# AE101F4071542LH_CM55_HE_View register map
Vendor: Alif Semiconductor; Series: E1; File version: 1.0
CPU: CM55 r1p0, selectable endian, MPU, FPU, double-precision FPU, DSP, VTOR, 8 interrupt priority bits, 1 SAU regions
Registers are 32-bit, read-write, reset 0x0 unless marked. A register's access mark holds for its fields unless they carry their own. Offsets are from the block's base; [hi:lo] are bit positions; {n}, {i} and the like mark numbered series.

## LPGPIO_CTRL
Base 0x42007000
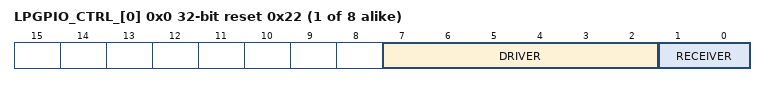
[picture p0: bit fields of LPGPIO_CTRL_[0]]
{0x0+4i} LPGPIO_CTRL_[{i}] (i=0..7) reset 0x22 — LPGPIO I/O Buffer Control Register
  [7:2] DRIVER — Driver configuration - Bit[7] selects driver mode: 0x0: Push-pull 0x1: Open drain - Bits[6-5] select driver strength: 0x0: 2 mA 0x1: 4 mA (default) 0x2: 8 mA 0x3: 12 mA - Bits[4-3] select driver disabled state: 0x0: Hi-Z 0x1: Pull-up 0x2: Pull-down 0x3: Bus keeper - Bit[2] selects slew rate: Note: Applicable only to 1.8-V I/Os (non-Flex) 0x0: Slow 0x1: Fast
  [1:0] RECEIVER — Receiver configuration - Bit[1] Schmitt trigger (hysteresis) enable: 0x0: Disabled 0x1: Enabled - Bit[0] receiver enable: 0x0: Disabled 0x1: Enabled

## LPCPI
Base 0x43003000
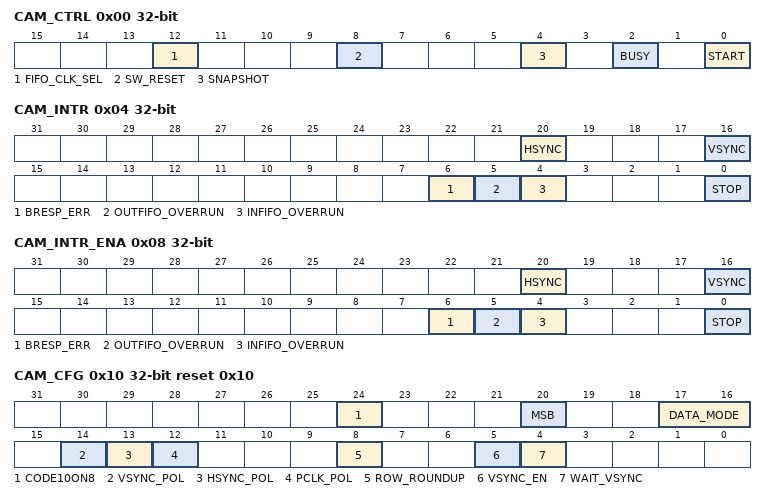
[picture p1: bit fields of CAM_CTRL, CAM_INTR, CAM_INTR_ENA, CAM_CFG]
0x00 CAM_CTRL — Camera Control Register
  [12] FIFO_CLK_SEL — Select clock source for the camera data input FIFO.
    0=Select internal clock for soft reset; 1=Select external camera clock for normal function mode
  [8] SW_RESET — Software reset. Software shall set then clear this bit.
    0=Not reset; 1=Reset
  [4] SNAPSHOT — Snapshot mode selection. Note: Setting this bit to value other than 1 will cause undefined behavior.
    1=Capture one frame then stop (snapshot mode)
  [2] BUSY ro — Status of video capture.
    0=Not capturing video; 1=Capturing video
  [0] START — Start video capture.
    0=No action; 1=Start video capture
0x04 CAM_INTR — Camera Interrupt Status Register
  [20] HSYNC wo write-1-clears — Rising edge of HSYNC signal.
  [16] VSYNC wo write-1-clears — Rising edge of VSYNC signal.
  [6] BRESP_ERR wo write-1-clears — AXI bus BRESP error.
  [5] OUTFIFO_OVERRUN wo write-1-clears — Output FIFO overrun.
  [4] INFIFO_OVERRUN wo write-1-clears — Input FIFO overrun.
  [0] STOP wo write-1-clears — Video capture stopped.
0x08 CAM_INTR_ENA — Camera Interrupt Enable Register
  [20] HSYNC — Rising edge of HSYNC signal.
  [16] VSYNC — Rising edge of VSYNC signal.
  [6] BRESP_ERR — AXI bus BRESP error.
  [5] OUTFIFO_OVERRUN — Output FIFO overrun.
  [4] INFIFO_OVERRUN — Input FIFO overrun.
  [0] STOP — Video capture stopped.
0x10 CAM_CFG reset 0x10 — Camera Configuration Register
  [24] CODE10ON8 — Special coding: transfer 10-bit coding over 8-bit data bus. Valid only when [DATA_MODE] field is set to 8-bit.
    0=Disable special 10-bit coding; 1=Enable special 10-bit coding
  [20] MSB — Select MSB/LSB Valid only when [DATA_MODE] field is set to 1-/2-/4-/8-bit.
    0=LSB; 1=MSB
  [17:16] DATA_MODE — Select video data mode.
    0=1-bit; 1=2-bit; 2=4-bit; 3=8-bit
  [14] VSYNC_POL — Set camera VSYNC polarity.
    0=Not invert VSYNC input; 1=Invert VSYNC input
  [13] HSYNC_POL — Set camera HSYNC polarity.
    0=Not invert HSYNC input; 1=Invert HSYNC input
  [12] PCLK_POL — Set camera PIXEL_CLK polarity.
    0=Not invert external camera PIXEL_CLK; 1=Invert external camera PIXEL_CLK
  [8] ROW_ROUNDUP — Round up pixel data to 64-bit at the end of each row.
    0=Not round up; 1=Round up pixel data to 64-bit at the end of each row
  [5] VSYNC_EN — Capture data when VSYNC is high.
    0=Capture data regardless of VSYNC status; 1=Capture data when VSYNC is high
  [4] WAIT_VSYNC — Capture video frame on the rising edge of VSYNC.
    0=Start video capture without waiting for VSYNC; 1=Start video capture on rising edge of VSYNC
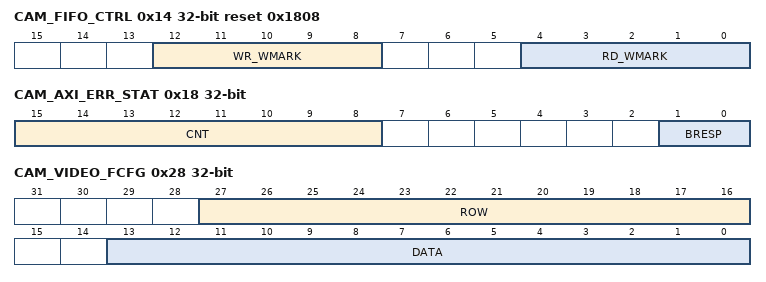
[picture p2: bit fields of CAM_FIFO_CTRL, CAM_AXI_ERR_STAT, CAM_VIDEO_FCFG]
0x14 CAM_FIFO_CTRL reset 0x1808 — Camera FIFO Control Register
  [12:8] WR_WMARK — Output FIFO write watermark.
  [4:0] RD_WMARK — Output FIFO read watermark.
0x18 CAM_AXI_ERR_STAT ro — Camera AXI Error Status Register
  [15:8] CNT — AXI bus BRESP error counter.
  [1:0] BRESP — AXI bus BRESP error code.
0x28 CAM_VIDEO_FCFG — Camera Video Frame Configuration Register
  [27:16] ROW — Valid data rows in a frame.
  [13:0] DATA — Valid data in a row. This value must match the camera output.
0x30 CAM_FRAME_ADDR — Camera Video Frame Start Address Register
  [31:3] ADDR — Video frame start address.
